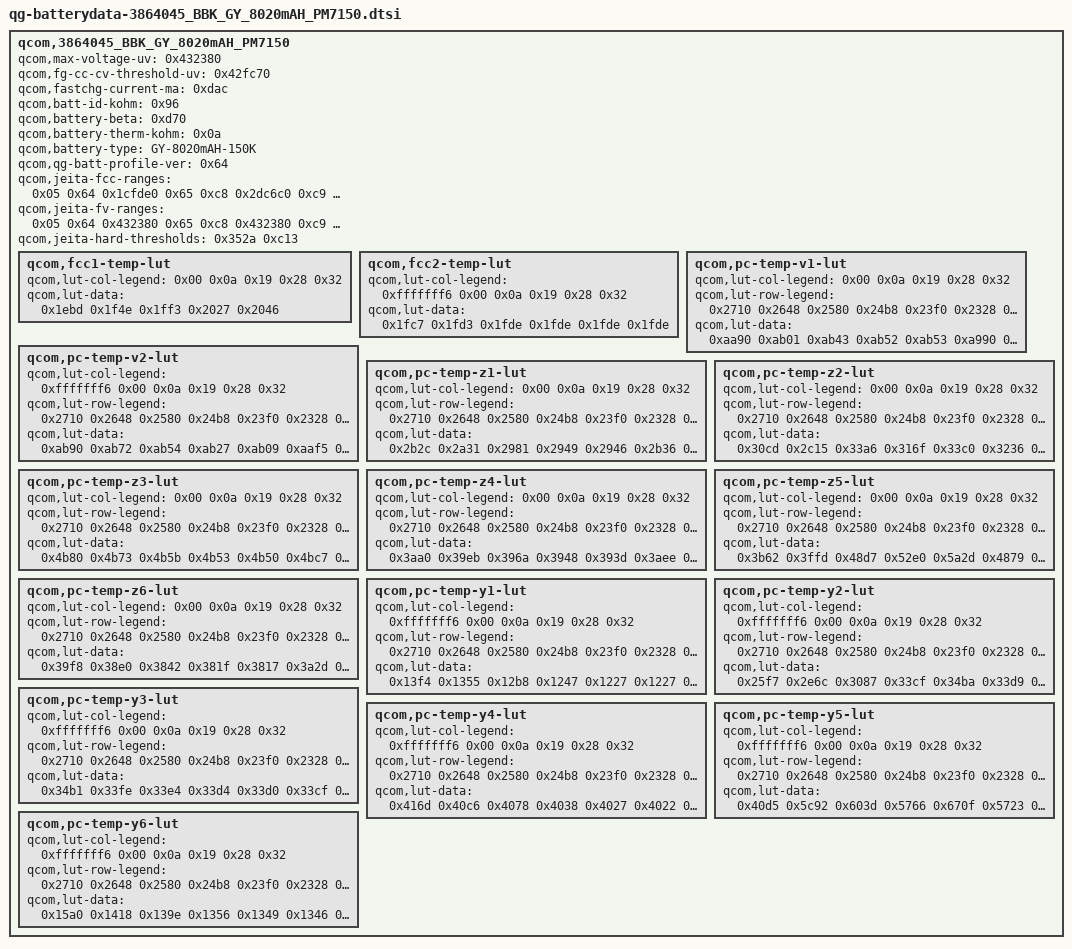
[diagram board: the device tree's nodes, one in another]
 /*
 * Copyright (c) 2026 XiKoTaSu <3329989998@qq.com>
 */

			qcom,3864045_BBK_GY_8020mAH_PM7150 {
				qcom,max-voltage-uv = <0x432380>;
				qcom,fg-cc-cv-threshold-uv = <0x42fc70>;
				qcom,fastchg-current-ma = <0xdac>;
				qcom,batt-id-kohm = <0x96>;
				qcom,battery-beta = <0xd70>;
				qcom,battery-therm-kohm = <0x0a>;
				qcom,battery-type = "GY-8020mAH-150K";
				qcom,qg-batt-profile-ver = <0x64>;
				qcom,jeita-fcc-ranges = <0x05 0x64 0x1cfde0 0x65 0xc8 0x2dc6c0 0xc9 0x1c2 0x3567e0 0x1c3 0x221 0x2625a0>;
				qcom,jeita-fv-ranges = <0x05 0x64 0x432380 0x65 0xc8 0x432380 0xc9 0x1c2 0x432380 0x1c3 0x221 0x3e8fa0>;
				qcom,jeita-hard-thresholds = <0x352a 0xc13>;

				qcom,fcc1-temp-lut {
					qcom,lut-col-legend = <0x00 0x0a 0x19 0x28 0x32>;
					qcom,lut-data = <0x1ebd 0x1f4e 0x1ff3 0x2027 0x2046>;
				};

				qcom,fcc2-temp-lut {
					qcom,lut-col-legend = <0xfffffff6 0x00 0x0a 0x19 0x28 0x32>;
					qcom,lut-data = <0x1fc7 0x1fd3 0x1fde 0x1fde 0x1fde 0x1fde>;
				};

				qcom,pc-temp-v1-lut {
					qcom,lut-col-legend = <0x00 0x0a 0x19 0x28 0x32>;
					qcom,lut-row-legend = <0x2710 0x2648 0x2580 0x24b8 0x23f0 0x2328 0x2260 0x2198 0x20d0 0x2008 0x1f40 0x1e78 0x1db0 0x1ce8 0x1c20 0x1b58 0x1a90 0x19c8 0x1900 0x1838 0x1770 0x16a8 0x15e0 0x1518 0x1450 0x1388 0x12c0 0x11f8 0x1130 0x1068 0xfa0 0xed8 0xe10 0xd48 0xc80 0xbb8 0xaf0 0xa28 0x960 0x898 0x7d0 0x708 0x640 0x578 0x4b0 0x3e8 0x384 0x320 0x2bc 0x258 0x1f4 0x190 0x12c 0xc8 0x64 0x00>;
					qcom,lut-data = <0xaa90 0xab01 0xab43 0xab52 0xab53 0xa990 0xaa10 0xaa6d 0xaa7b 0xaa7d 0xa895 0xa921 0xa98e 0xa9a4 0xa9ab 0xa7a1 0xa834 0xa8aa 0xa8c8 0xa8d4 0xa6b7 0xa749 0xa7bd 0xa7e4 0xa7f3 0xa5d5 0xa65f 0xa6cf 0xa6fb 0xa70b 0xa4fa 0xa579 0xa5e4 0xa613 0xa623 0xa427 0xa499 0xa4fb 0xa529 0xa53a 0xa35b 0xa3c0 0xa416 0xa442 0xa454 0xa290 0xa2eb 0xa334 0xa35d 0xa36e 0xa1c6 0xa21a 0xa256 0xa279 0xa28a 0xa105 0xa14b 0xa17f 0xa19d 0xa1ad 0xa059 0xa08b 0xa0ae 0xa0c3 0xa0d3 0x9fb5 0x9fe9 0x9fea 0x9ff3 0xa000 0x9ee5 0x9f42 0x9f38 0x9f2b 0x9f31 0x9daa 0x9e54 0x9e7e 0x9e69 0x9e67 0x9c7f 0x9d15 0x9d93 0x9da6 0x9da6 0x9bdb 0x9c25 0x9c99 0x9ce4 0x9ced 0x9b6e 0x9bb3 0x9be4 0x9c30 0x9c3b 0x9aff 0x9b54 0x9b6b 0x9b95 0x9b9b 0x9a87 0x9aa9 0x9ae6 0x9af6 0x9af8 0x9a04 0x9985 0x9a08 0x9a21 0x9a2b 0x9951 0x9892 0x98fc 0x9920 0x992f 0x984b 0x9813 0x983b 0x9854 0x985d 0x977c 0x97b2 0x97ae 0x97be 0x97c3 0x9722 0x9751 0x9737 0x973f 0x9741 0x96e5 0x96f2 0x96cc 0x96cc 0x96cc 0x96ac 0x969a 0x966c 0x9664 0x9663 0x9676 0x964a 0x9614 0x9606 0x9604 0x9644 0x9601 0x95c2 0x95af 0x95aa 0x9613 0x95c1 0x9579 0x9560 0x9558 0x95e3 0x9587 0x9537 0x9519 0x950e 0x95b9 0x9554 0x94fd 0x94d8 0x94ca 0x9595 0x952d 0x94cc 0x949f 0x948b 0x9574 0x950e 0x94a4 0x946e 0x9455 0x9555 0x94ed 0x947d 0x943f 0x941e 0x9539 0x94cf 0x9457 0x940a 0x93dd 0x9514 0x94aa 0x942f 0x93d2 0x9393 0x94cc 0x946d 0x93f5 0x938c 0x9342 0x9462 0x940b 0x939b 0x9332 0x92e8 0x93ef 0x939c 0x9330 0x92c9 0x9280 0x9369 0x931e 0x92b6 0x924e 0x9203 0x92d4 0x928f 0x922a 0x91c2 0x9173 0x9226 0x91e3 0x9188 0x9123 0x90d6 0x91c7 0x9160 0x9104 0x90a8 0x9064 0x9178 0x9118 0x90bf 0x9066 0x902a 0x915c 0x9103 0x90ac 0x9054 0x901c 0x9142 0x90fa 0x909d 0x904a 0x900f 0x9120 0x90e0 0x908c 0x9032 0x8ff0 0x90a6 0x9075 0x900c 0x8f98 0x8f2b 0x8f30 0x8f0b 0x8ea3 0x8e2e 0x8db4 0x8d42 0x8d28 0x8cc5 0x8c4f 0x8bcd 0x8aca 0x8abe 0x8a5d 0x89e8 0x8958 0x8765 0x876e 0x8711 0x869f 0x85f9 0x81f9 0x8236 0x81e4 0x8181 0x80a7 0x7530 0x7530 0x7530 0x7530 0x7530>;
				};

				qcom,pc-temp-v2-lut {
					qcom,lut-col-legend = <0xfffffff6 0x00 0x0a 0x19 0x28 0x32>;
					qcom,lut-row-legend = <0x2710 0x2648 0x2580 0x24b8 0x23f0 0x2328 0x2260 0x2198 0x20d0 0x2008 0x1f40 0x1e78 0x1db0 0x1ce8 0x1c20 0x1b58 0x1a90 0x19c8 0x1900 0x1838 0x1770 0x16a8 0x15e0 0x1518 0x1450 0x1388 0x12c0 0x11f8 0x1130 0x1068 0xfa0 0xed8 0xe10 0xd48 0xc80 0xbb8 0xaf0 0xa28 0x960 0x898 0x7d0 0x708 0x640 0x578 0x4b0 0x3e8 0x384 0x320 0x2bc 0x258 0x1f4 0x190 0x12c 0xc8 0x64 0x00>;
					qcom,lut-data = <0xab90 0xab72 0xab54 0xab27 0xab09 0xaaf5 0xa9f3 0xaa3a 0xaa49 0xaa27 0xaa14 0xaa02 0xa87e 0xa913 0xa945 0xa92c 0xa922 0xa913 0xa735 0xa800 0xa84a 0xa837 0xa833 0xa826 0xa60e 0xa700 0xa755 0xa749 0xa748 0xa73d 0xa50a 0xa609 0xa665 0xa65d 0xa65e 0xa654 0xa431 0xa515 0xa579 0xa572 0xa574 0xa56b 0xa36c 0xa428 0xa490 0xa489 0xa48b 0xa481 0xa28c 0xa344 0xa3ae 0xa3a5 0xa3a6 0xa39c 0xa183 0xa265 0xa2d3 0xa2c4 0xa2c2 0xa2b9 0xa0bf 0xa193 0xa1fb 0xa1e6 0xa1e2 0xa1d9 0xa06e 0xa0dc 0xa121 0xa10a 0xa106 0xa0fd 0xa030 0xa02b 0xa04b 0xa032 0xa02e 0xa024 0x9f6b 0x9f5c 0x9f89 0x9f6e 0x9f60 0x9f54 0x9d0b 0x9e6c 0x9edd 0x9ebe 0x9e99 0x9e88 0x9b08 0x9d6c 0x9e1c 0x9e02 0x9dd8 0x9dc4 0x9a55 0x9c51 0x9d11 0x9d12 0x9d15 0x9d07 0x99d9 0x9b33 0x9bee 0x9c19 0x9c57 0x9c51 0x9937 0x9a55 0x9b13 0x9b66 0x9ba6 0x9ba2 0x986b 0x99ab 0x9a6d 0x9ae6 0x9b06 0x9aff 0x979f 0x9904 0x99c4 0x9a54 0x9a56 0x9a4c 0x96d7 0x9849 0x98f5 0x9968 0x9966 0x995d 0x961e 0x9790 0x9824 0x985e 0x9866 0x9860 0x95a5 0x96f4 0x977d 0x97a0 0x97ac 0x97a8 0x9553 0x966f 0x96f4 0x9712 0x971e 0x971c 0x9513 0x95f5 0x967a 0x9697 0x96a4 0x96a2 0x94e1 0x957e 0x960b 0x9629 0x9635 0x9632 0x94b6 0x9511 0x95a7 0x95c6 0x95d1 0x95cd 0x948d 0x94bb 0x954a 0x956b 0x9575 0x956f 0x9465 0x9474 0x94f4 0x9516 0x951f 0x9518 0x943e 0x943b 0x94a5 0x94ca 0x94d1 0x94c9 0x9416 0x9413 0x945c 0x9485 0x948b 0x9483 0x93ed 0x93f1 0x9419 0x9446 0x9449 0x9440 0x93c0 0x93ce 0x93e3 0x9406 0x9405 0x93f8 0x9390 0x93aa 0x93b7 0x93c7 0x93c1 0x93ab 0x935a 0x9383 0x938c 0x9387 0x9376 0x9355 0x931e 0x9358 0x935f 0x9345 0x931a 0x92ec 0x92da 0x9327 0x932f 0x9302 0x92b6 0x927a 0x928d 0x92e4 0x92f2 0x92bb 0x925d 0x921b 0x9230 0x9284 0x92a4 0x9271 0x9210 0x91ca 0x91d1 0x9216 0x9248 0x921c 0x91bb 0x9172 0x9176 0x9196 0x91d9 0x91af 0x9150 0x9101 0x911f 0x9117 0x915b 0x9131 0x90d4 0x9084 0x90ca 0x90b9 0x90ca 0x908e 0x9034 0x8fe9 0x9073 0x9072 0x9072 0x903c 0x8fee 0x8fae 0x9009 0x9027 0x9045 0x901d 0x8fd7 0x8f9b 0x8fb4 0x8ff4 0x902c 0x900d 0x8fc9 0x8f8b 0x8f4b 0x8f93 0x900a 0x8ff9 0x8fb2 0x8f6f 0x8ec2 0x8f05 0x8fc6 0x8fd1 0x8f83 0x8f32 0x8e22 0x8e1e 0x8f22 0x8f48 0x8ecd 0x8e20 0x8d2a 0x8ccb 0x8dde 0x8dd1 0x8d3a 0x8c6c 0x8bae 0x8b1f 0x8bf1 0x8bcf 0x8b2b 0x8a3b 0x8966 0x88d0 0x8956 0x892e 0x887c 0x875b 0x85ec 0x8576 0x85af 0x8594 0x84b8 0x8332 0x7fb3 0x7fb4 0x7fa3 0x7fc5 0x7eb8 0x7c9d 0x6b66 0x6a63 0x7045 0x7061 0x7126 0x6dff>;
				};

				qcom,pc-temp-z1-lut {
					qcom,lut-col-legend = <0x00 0x0a 0x19 0x28 0x32>;
					qcom,lut-row-legend = <0x2710 0x2648 0x2580 0x24b8 0x23f0 0x2328 0x2260 0x2198 0x20d0 0x2008 0x1f40 0x1e78 0x1db0 0x1ce8 0x1c20 0x1b58 0x1a90 0x19c8 0x1900 0x1838 0x1770 0x16a8 0x15e0 0x1518 0x1450 0x1388 0x12c0 0x11f8 0x1130 0x1068 0xfa0 0xed8 0xe10 0xd48 0xc80 0xbb8 0xaf0 0xa28 0x960 0x898 0x7d0 0x708 0x640 0x578 0x4b0 0x3e8 0x384 0x320 0x2bc 0x258 0x1f4 0x190 0x12c 0xc8 0x64 0x00>;
					qcom,lut-data = <0x2b2c 0x2a31 0x2981 0x2949 0x2946 0x2b36 0x2a41 0x2999 0x295d 0x295f 0x2b39 0x2a48 0x29a0 0x2964 0x2965 0x2b3a 0x2a4a 0x29a1 0x2967 0x2968 0x2b3c 0x2a4b 0x29a0 0x2969 0x296a 0x2b3d 0x2a4b 0x29a0 0x296a 0x296c 0x2b3d 0x2a49 0x29a1 0x296c 0x296e 0x2b3b 0x2a48 0x29a2 0x296d 0x2971 0x2b39 0x2a48 0x29a2 0x296d 0x2972 0x2b38 0x2a48 0x29a2 0x296d 0x2972 0x2b36 0x2a48 0x29a1 0x296c 0x2972 0x2b35 0x2a4a 0x29a1 0x296c 0x2972 0x2b35 0x2a4a 0x29a1 0x296c 0x2972 0x2b37 0x2a44 0x29a0 0x296c 0x2972 0x2b36 0x2a3b 0x299e 0x296c 0x2972 0x2b2e 0x2a39 0x299c 0x296c 0x2972 0x2b26 0x2a3a 0x299c 0x296c 0x2972 0x2b25 0x2a3a 0x299b 0x296c 0x2973 0x2b27 0x2a3b 0x299c 0x296c 0x2973 0x2b29 0x2a3b 0x299e 0x296d 0x2973 0x2b2b 0x2a3c 0x29a0 0x296e 0x2974 0x2b2e 0x2a3c 0x29a1 0x296f 0x2974 0x2b32 0x2a3d 0x29a3 0x2970 0x2976 0x2b3a 0x2a3e 0x29a4 0x2971 0x2977 0x2b41 0x2a3e 0x29a6 0x2971 0x2977 0x2b40 0x2a40 0x29a8 0x2972 0x2978 0x2b3e 0x2a44 0x29a8 0x2972 0x2979 0x2b3f 0x2a49 0x29a9 0x2973 0x297a 0x2b44 0x2a4a 0x29ab 0x2974 0x297a 0x2b48 0x2a4a 0x29ae 0x2975 0x297c 0x2b48 0x2a4b 0x29b1 0x2977 0x297d 0x2b48 0x2a4a 0x29b2 0x2978 0x297d 0x2b48 0x2a4a 0x29b2 0x2979 0x297e 0x2b4a 0x2a4b 0x29b2 0x297a 0x297f 0x2b4b 0x2a4b 0x29b3 0x297b 0x297f 0x2b4c 0x2a4d 0x29b4 0x297c 0x2980 0x2b4d 0x2a50 0x29b6 0x297d 0x2981 0x2b4f 0x2a53 0x29b8 0x297e 0x2982 0x2b55 0x2a53 0x29ba 0x297f 0x2983 0x2b5d 0x2a53 0x29bc 0x2980 0x2983 0x2b60 0x2a53 0x29bd 0x2981 0x2984 0x2b5f 0x2a59 0x29be 0x2982 0x2985 0x2b5c 0x2a5e 0x29be 0x2983 0x2986 0x2b4a 0x2a5f 0x29bf 0x2985 0x2986 0x2b4d 0x2a61 0x29c1 0x2985 0x2987 0x2b56 0x2a59 0x29c2 0x2985 0x2987 0x2b57 0x2a5c 0x29c4 0x2986 0x2988 0x2b50 0x2a5e 0x29c4 0x2986 0x2987 0x2b62 0x2a5a 0x29c2 0x2986 0x2987 0x2b60 0x2a60 0x29c6 0x2988 0x2989 0x2b56 0x2a63 0x29c9 0x298a 0x298b 0x2b5b 0x2a64 0x29ce 0x298d 0x298e 0x2b69 0x2a6a 0x29d1 0x2991 0x2991 0x2b7e 0x2a79 0x29d6 0x2996 0x2995 0x2b7e 0x2a79 0x29d6 0x2996 0x2995 0x2b7e 0x2a79 0x29d6 0x2996 0x2995>;
				};

				qcom,pc-temp-z2-lut {
					qcom,lut-col-legend = <0x00 0x0a 0x19 0x28 0x32>;
					qcom,lut-row-legend = <0x2710 0x2648 0x2580 0x24b8 0x23f0 0x2328 0x2260 0x2198 0x20d0 0x2008 0x1f40 0x1e78 0x1db0 0x1ce8 0x1c20 0x1b58 0x1a90 0x19c8 0x1900 0x1838 0x1770 0x16a8 0x15e0 0x1518 0x1450 0x1388 0x12c0 0x11f8 0x1130 0x1068 0xfa0 0xed8 0xe10 0xd48 0xc80 0xbb8 0xaf0 0xa28 0x960 0x898 0x7d0 0x708 0x640 0x578 0x4b0 0x3e8 0x384 0x320 0x2bc 0x258 0x1f4 0x190 0x12c 0xc8 0x64 0x00>;
					qcom,lut-data = <0x30cd 0x2c15 0x33a6 0x316f 0x33c0 0x3236 0x2e8c 0x30f5 0x3098 0x31bb 0x3033 0x2f43 0x30df 0x30bf 0x3165 0x2e33 0x2f3c 0x30e4 0x30e3 0x312f 0x2dea 0x2f30 0x30f5 0x30ab 0x30d9 0x2dc2 0x2f11 0x30fd 0x305e 0x3076 0x2d99 0x2ede 0x30e4 0x304f 0x3058 0x2d6d 0x2ec8 0x30c3 0x3045 0x3070 0x2d45 0x2ec9 0x30b8 0x304e 0x3086 0x2d2f 0x2ecb 0x30c5 0x307f 0x3097 0x2d21 0x2ecf 0x30cd 0x30b3 0x30b8 0x2d1a 0x2edd 0x30aa 0x30b8 0x30cb 0x2d8d 0x2eeb 0x306c 0x30a2 0x30d8 0x2e69 0x2f09 0x3052 0x3098 0x30e6 0x2ea0 0x2f25 0x304a 0x30a9 0x30f7 0x2e06 0x2f0e 0x303f 0x30bd 0x3108 0x2d68 0x2ea9 0x2ffc 0x30bd 0x3118 0x2d46 0x2e72 0x2f91 0x30b6 0x3129 0x2d2f 0x2ea3 0x2f7f 0x30b7 0x3139 0x2d28 0x2eea 0x2fcd 0x30f1 0x3175 0x2d50 0x2eff 0x3042 0x3147 0x31b9 0x2d87 0x2f03 0x3101 0x319a 0x31ae 0x2d88 0x2f06 0x31e0 0x31fb 0x3153 0x2d57 0x2f11 0x31f8 0x320a 0x30da 0x2d33 0x2f1f 0x312c 0x30c6 0x2ff7 0x2d52 0x2f21 0x306d 0x2f7d 0x2f2c 0x2d91 0x2f13 0x3023 0x2f61 0x2f20 0x2da5 0x2f00 0x2ff2 0x2f61 0x2f37 0x2da2 0x2ee5 0x2fed 0x2f6d 0x2f58 0x2d9f 0x2ec5 0x300e 0x2f8d 0x2f93 0x2da2 0x2ebf 0x302e 0x2fb5 0x2fde 0x2dad 0x2edb 0x3046 0x2ff4 0x301f 0x2db6 0x2f00 0x306d 0x3065 0x3060 0x2dc2 0x2f1b 0x30a8 0x30ce 0x30b4 0x2dcd 0x2f36 0x3119 0x3138 0x3138 0x2dd1 0x2f4f 0x317a 0x319e 0x31bf 0x2dd9 0x2f68 0x31a8 0x3202 0x322e 0x2de3 0x2f83 0x31cb 0x3262 0x3292 0x2df1 0x2fa9 0x31f6 0x3292 0x32b1 0x2e00 0x2fd9 0x3231 0x32ac 0x329e 0x2e03 0x2feb 0x3250 0x32b2 0x3287 0x2df5 0x2fd3 0x323c 0x3299 0x327c 0x2de3 0x2fbc 0x320a 0x326f 0x3269 0x2dca 0x2fa0 0x318e 0x323a 0x3223 0x2f8a 0x2fa0 0x317e 0x323c 0x31ea 0x33ba 0x2f95 0x319b 0x3246 0x321d 0x348d 0x2f6a 0x3154 0x3244 0x3237 0x39eb 0x2f3c 0x3155 0x32bb 0x3276 0x3d3e 0x2f3f 0x31e7 0x33a8 0x33d3 0x3928 0x2fe2 0x327f 0x328e 0x314c 0x40f9 0x3015 0x319c 0x3107 0x303a 0x3197 0x2fe8 0x3132 0x3076 0x2fe0 0x2cdb 0x2f18 0x311d 0x3026 0x2f61 0x29ec 0x2e1f 0x303c 0x2f76 0x2eac 0x29ec 0x2e1f 0x303c 0x2f76 0x2eac 0x29ec 0x2e1f 0x303c 0x2f76 0x2eac>;
				};

				qcom,pc-temp-z3-lut {
					qcom,lut-col-legend = <0x00 0x0a 0x19 0x28 0x32>;
					qcom,lut-row-legend = <0x2710 0x2648 0x2580 0x24b8 0x23f0 0x2328 0x2260 0x2198 0x20d0 0x2008 0x1f40 0x1e78 0x1db0 0x1ce8 0x1c20 0x1b58 0x1a90 0x19c8 0x1900 0x1838 0x1770 0x16a8 0x15e0 0x1518 0x1450 0x1388 0x12c0 0x11f8 0x1130 0x1068 0xfa0 0xed8 0xe10 0xd48 0xc80 0xbb8 0xaf0 0xa28 0x960 0x898 0x7d0 0x708 0x640 0x578 0x4b0 0x3e8 0x384 0x320 0x2bc 0x258 0x1f4 0x190 0x12c 0xc8 0x64 0x00>;
					qcom,lut-data = <0x4b80 0x4b73 0x4b5b 0x4b53 0x4b50 0x4bc7 0x4b8f 0x4b67 0x4b59 0x4b55 0x4bd1 0x4b9c 0x4b6f 0x4b5e 0x4b57 0x4bdd 0x4ba3 0x4b73 0x4b60 0x4b58 0x4be1 0x4ba6 0x4b76 0x4b61 0x4b5a 0x4be3 0x4ba7 0x4b77 0x4b61 0x4b5c 0x4be4 0x4ba7 0x4b77 0x4b61 0x4b5c 0x4be4 0x4ba7 0x4b76 0x4b61 0x4b5c 0x4be3 0x4ba5 0x4b75 0x4b60 0x4b5c 0x4be3 0x4ba3 0x4b74 0x4b60 0x4b5b 0x4be2 0x4ba1 0x4b73 0x4b60 0x4b5b 0x4be1 0x4b9f 0x4b71 0x4b5e 0x4b5a 0x4bdc 0x4b9d 0x4b6f 0x4b5b 0x4b58 0x4bd3 0x4b98 0x4b6d 0x4b5a 0x4b57 0x4bd0 0x4b93 0x4b6c 0x4b5a 0x4b56 0x4bd6 0x4b95 0x4b6c 0x4b5a 0x4b56 0x4bdc 0x4b9d 0x4b6c 0x4b5a 0x4b56 0x4bda 0x4ba2 0x4b6d 0x4b59 0x4b55 0x4bd2 0x4b9c 0x4b6d 0x4b59 0x4b54 0x4bcc 0x4b93 0x4b69 0x4b58 0x4b53 0x4bcb 0x4b93 0x4b67 0x4b57 0x4b52 0x4bca 0x4b98 0x4b69 0x4b5a 0x4b55 0x4bca 0x4b9b 0x4b6f 0x4b64 0x4b5f 0x4bcc 0x4b98 0x4b75 0x4b68 0x4b63 0x4bce 0x4b94 0x4b7d 0x4b68 0x4b63 0x4bcf 0x4b95 0x4b81 0x4b67 0x4b63 0x4bd0 0x4b9e 0x4b80 0x4b67 0x4b62 0x4bd0 0x4ba5 0x4b7c 0x4b66 0x4b5f 0x4bd0 0x4ba5 0x4b7a 0x4b65 0x4b5d 0x4bd0 0x4ba3 0x4b78 0x4b63 0x4b5b 0x4bd1 0x4ba2 0x4b77 0x4b61 0x4b5a 0x4bd1 0x4ba0 0x4b75 0x4b60 0x4b58 0x4bd0 0x4b9e 0x4b73 0x4b5e 0x4b57 0x4bcf 0x4b9c 0x4b71 0x4b5d 0x4b56 0x4bcd 0x4b99 0x4b6f 0x4b5b 0x4b54 0x4bcb 0x4b97 0x4b6d 0x4b5a 0x4b53 0x4bc9 0x4b96 0x4b6d 0x4b59 0x4b53 0x4bc7 0x4b95 0x4b6c 0x4b59 0x4b54 0x4bc4 0x4b93 0x4b6b 0x4b59 0x4b55 0x4bc1 0x4b91 0x4b69 0x4b59 0x4b56 0x4bc0 0x4b8e 0x4b68 0x4b59 0x4b57 0x4bbf 0x4b8d 0x4b67 0x4b5a 0x4b57 0x4bbe 0x4b8c 0x4b67 0x4b5a 0x4b58 0x4bba 0x4b8c 0x4b66 0x4b5b 0x4b59 0x4b54 0x4b87 0x4b65 0x4b5a 0x4b58 0x4b39 0x4b82 0x4b61 0x4b57 0x4b55 0x4b39 0x4b81 0x4b5f 0x4b56 0x4b50 0x4b39 0x4b72 0x4b60 0x4b51 0x4b4e 0x4b39 0x4b6c 0x4b5a 0x4b4f 0x4b4c 0x4b39 0x4b69 0x4b5b 0x4b54 0x4b53 0x4b39 0x4b66 0x4b60 0x4b57 0x4b55 0x4b3a 0x4b64 0x4b5f 0x4b59 0x4b55 0x4b3b 0x4b62 0x4b5c 0x4b58 0x4b56 0x4b3c 0x4b62 0x4b5d 0x4b5a 0x4b57 0x4b3c 0x4b62 0x4b5d 0x4b5a 0x4b57 0x4b3c 0x4b62 0x4b5d 0x4b5a 0x4b57>;
				};

				qcom,pc-temp-z4-lut {
					qcom,lut-col-legend = <0x00 0x0a 0x19 0x28 0x32>;
					qcom,lut-row-legend = <0x2710 0x2648 0x2580 0x24b8 0x23f0 0x2328 0x2260 0x2198 0x20d0 0x2008 0x1f40 0x1e78 0x1db0 0x1ce8 0x1c20 0x1b58 0x1a90 0x19c8 0x1900 0x1838 0x1770 0x16a8 0x15e0 0x1518 0x1450 0x1388 0x12c0 0x11f8 0x1130 0x1068 0xfa0 0xed8 0xe10 0xd48 0xc80 0xbb8 0xaf0 0xa28 0x960 0x898 0x7d0 0x708 0x640 0x578 0x4b0 0x3e8 0x384 0x320 0x2bc 0x258 0x1f4 0x190 0x12c 0xc8 0x64 0x00>;
					qcom,lut-data = <0x3aa0 0x39eb 0x396a 0x3948 0x393d 0x3aee 0x3a20 0x3999 0x395c 0x394a 0x3ac2 0x3a28 0x398d 0x3958 0x3948 0x3a83 0x39f8 0x3980 0x3953 0x3944 0x3a4c 0x39c0 0x396f 0x394b 0x393f 0x3a15 0x39a0 0x395e 0x3942 0x3938 0x39e6 0x3988 0x3950 0x393a 0x3932 0x39c1 0x3973 0x3944 0x3933 0x392d 0x39a3 0x3960 0x393d 0x392e 0x3928 0x398f 0x3952 0x3938 0x392b 0x3926 0x3982 0x3950 0x3936 0x3928 0x3924 0x3975 0x3950 0x3935 0x3927 0x3922 0x3962 0x394f 0x3935 0x3925 0x3920 0x394d 0x3946 0x3934 0x3923 0x391e 0x3949 0x393c 0x392d 0x3920 0x391c 0x3963 0x393d 0x3928 0x391c 0x3919 0x397f 0x3948 0x3928 0x3919 0x3917 0x397a 0x394e 0x3928 0x3917 0x3915 0x3962 0x3942 0x3928 0x3916 0x3913 0x3952 0x3931 0x3925 0x3916 0x3912 0x394d 0x393c 0x3923 0x3916 0x3912 0x394a 0x3980 0x393a 0x391f 0x3917 0x3956 0x39ad 0x3964 0x3939 0x392c 0x3997 0x39a7 0x396c 0x3943 0x3937 0x39c7 0x399a 0x395a 0x393d 0x3932 0x39bf 0x398a 0x3949 0x3934 0x392b 0x39ac 0x3973 0x3942 0x392f 0x3927 0x399c 0x3962 0x393e 0x392c 0x3925 0x398d 0x395a 0x393a 0x3928 0x3922 0x3980 0x3955 0x3937 0x3926 0x3920 0x3978 0x3954 0x3936 0x3924 0x391f 0x3971 0x3955 0x3936 0x3922 0x391d 0x396b 0x3956 0x3936 0x3921 0x391b 0x3968 0x3955 0x3936 0x3921 0x391b 0x3964 0x3954 0x3937 0x3921 0x391b 0x3960 0x3952 0x3937 0x3922 0x391b 0x395a 0x394f 0x3938 0x3924 0x391d 0x3956 0x394d 0x3938 0x3927 0x3922 0x3956 0x394c 0x3938 0x3928 0x3923 0x3956 0x394c 0x3938 0x3928 0x3922 0x3956 0x394b 0x3937 0x3927 0x3920 0x3951 0x3945 0x3933 0x3924 0x391f 0x394c 0x393e 0x392f 0x3922 0x391e 0x3947 0x393b 0x392e 0x3922 0x391f 0x398f 0x392f 0x3928 0x3920 0x391c 0x399e 0x3922 0x391d 0x3916 0x3912 0x3999 0x391d 0x3917 0x3912 0x3910 0x3996 0x3924 0x3910 0x390d 0x390a 0x3990 0x3927 0x3910 0x390a 0x3907 0x398d 0x392a 0x3915 0x390d 0x390d 0x3996 0x3934 0x3914 0x390d 0x390d 0x399a 0x3939 0x3915 0x390c 0x390d 0x399e 0x393e 0x3918 0x390d 0x390c 0x39a8 0x3942 0x3919 0x390c 0x390c 0x39a8 0x3942 0x3919 0x390c 0x390c 0x39a8 0x3942 0x3919 0x390c 0x390c>;
				};

				qcom,pc-temp-z5-lut {
					qcom,lut-col-legend = <0x00 0x0a 0x19 0x28 0x32>;
					qcom,lut-row-legend = <0x2710 0x2648 0x2580 0x24b8 0x23f0 0x2328 0x2260 0x2198 0x20d0 0x2008 0x1f40 0x1e78 0x1db0 0x1ce8 0x1c20 0x1b58 0x1a90 0x19c8 0x1900 0x1838 0x1770 0x16a8 0x15e0 0x1518 0x1450 0x1388 0x12c0 0x11f8 0x1130 0x1068 0xfa0 0xed8 0xe10 0xd48 0xc80 0xbb8 0xaf0 0xa28 0x960 0x898 0x7d0 0x708 0x640 0x578 0x4b0 0x3e8 0x384 0x320 0x2bc 0x258 0x1f4 0x190 0x12c 0xc8 0x64 0x00>;
					qcom,lut-data = <0x3b62 0x3ffd 0x48d7 0x52e0 0x5a2d 0x4879 0x4f03 0x588e 0x62c5 0x6b03 0x4f72 0x5963 0x601d 0x6e6c 0x6e66 0x5650 0x603b 0x6611 0x7458 0x7232 0x5c33 0x664f 0x6b3d 0x74e8 0x7792 0x6112 0x6ced 0x7037 0x7540 0x7e09 0x66a1 0x739f 0x7631 0x76eb 0x8358 0x6e29 0x7bb9 0x7c57 0x7bd0 0x8819 0x771c 0x8826 0x80a0 0x80ba 0x8c11 0x8111 0x9310 0x8498 0x857f 0x909c 0x8df6 0x966e 0x86d1 0x8919 0x9522 0x95c2 0x96b5 0x83a3 0x8772 0x94da 0x9547 0x963c 0x7d53 0x8044 0x8e92 0x93fd 0x938e 0x7c33 0x7ce9 0x8a86 0x938e 0x9110 0x815c 0x8102 0x8f7c 0x9405 0x9352 0x87b7 0x884b 0x98f7 0x94c8 0x99ae 0x8c69 0x9135 0xa0df 0x95a9 0xa0b6 0x9143 0x9ce0 0xa8bf 0x978d 0xa6b2 0x979f 0xa1f0 0xad1e 0x9b13 0xadd2 0xa19e 0xa1fd 0xaeb8 0xb2e1 0xbc62 0xa7d0 0xa0d3 0xafa4 0xd4d8 0xdae1 0x9af0 0x9bcf 0xac2a 0xe3e1 0xecce 0x82f4 0x9008 0x9e44 0xec8c 0xc626 0x7d62 0x865d 0x9278 0xee7f 0x8662 0x8114 0x7d15 0x8ad7 0xde79 0x799a 0x862a 0x76c3 0x855d 0xc3bc 0x8a34 0x8b46 0x79dd 0x849c 0xb9a4 0x9ef3 0x916f 0x840c 0x87ce 0xb862 0xb0bc 0x99b7 0x8cf3 0x8970 0xb8d9 0xc2d3 0xa89a 0x93a3 0x8af0 0xbfbf 0xd205 0xb654 0x9adf 0x8e1e 0xd1e5 0xe08f 0xc15b 0xa578 0x9450 0xdfec 0xe9d5 0xccc5 0xb21d 0x9e2f 0xe938 0xebb0 0xd360 0xba1c 0xa4f5 0xf02d 0xec99 0xd7ef 0xbfb6 0xa9e4 0xf19f 0xed24 0xd9fd 0xc2a5 0xacca 0xf187 0xef9a 0xd75f 0xbaf8 0xac5b 0xf19e 0xf1fd 0xd0d3 0xaaf4 0xab1b 0xf3d9 0xedba 0xc78c 0xa62c 0xab72 0xf721 0xdf8a 0xb6b5 0xa5eb 0xb39c 0xf6e7 0xd4cf 0xab42 0xa5e5 0xbd48 0xec43 0xcd36 0xa9a5 0xaa49 0xc3d1 0xe0b5 0xc7b9 0xa825 0xafef 0xc7e9 0xd6d4 0xc520 0x98ff 0xabaf 0xc486 0x540e 0xc32d 0x9bb5 0x9c27 0xb444 0x333e 0xb948 0x9532 0x9510 0xa2ce 0x328f 0xbf66 0x9ba3 0xa099 0x87a0 0x3248 0x6e55 0xb53d 0x96f5 0x9f2b 0x3249 0x621d 0x8d04 0x9fcc 0xaf5c 0x32eb 0x5e74 0x82a6 0x9ed5 0xb2e9 0x32f4 0x52da 0x8a4b 0x9c98 0xad17 0x3278 0x4d0c 0x7cfc 0xa5d7 0xa613 0x3202 0x47c6 0x68b8 0x9787 0xa969 0x3126 0x44bb 0x6522 0x9b4f 0xa49f 0x3126 0x44bb 0x6522 0x9b4f 0xa49f 0x3126 0x44bb 0x6522 0x9b4f 0xa49f>;
				};

				qcom,pc-temp-z6-lut {
					qcom,lut-col-legend = <0x00 0x0a 0x19 0x28 0x32>;
					qcom,lut-row-legend = <0x2710 0x2648 0x2580 0x24b8 0x23f0 0x2328 0x2260 0x2198 0x20d0 0x2008 0x1f40 0x1e78 0x1db0 0x1ce8 0x1c20 0x1b58 0x1a90 0x19c8 0x1900 0x1838 0x1770 0x16a8 0x15e0 0x1518 0x1450 0x1388 0x12c0 0x11f8 0x1130 0x1068 0xfa0 0xed8 0xe10 0xd48 0xc80 0xbb8 0xaf0 0xa28 0x960 0x898 0x7d0 0x708 0x640 0x578 0x4b0 0x3e8 0x384 0x320 0x2bc 0x258 0x1f4 0x190 0x12c 0xc8 0x64 0x00>;
					qcom,lut-data = <0x39f8 0x38e0 0x3842 0x381f 0x3817 0x3a2d 0x3901 0x385c 0x382d 0x3824 0x3a0f 0x3907 0x385d 0x382f 0x3826 0x39e1 0x38f1 0x385c 0x3830 0x3826 0x39bd 0x38d6 0x3855 0x382e 0x3825 0x399b 0x38c4 0x384e 0x382a 0x3824 0x397e 0x38b6 0x3848 0x3827 0x3822 0x3965 0x38aa 0x3842 0x3824 0x3820 0x3950 0x389d 0x383e 0x3822 0x381e 0x3941 0x3894 0x383b 0x3820 0x381d 0x3936 0x3891 0x3839 0x381f 0x381b 0x392b 0x3890 0x3838 0x381d 0x381a 0x391b 0x388d 0x3837 0x381b 0x3818 0x390a 0x3885 0x3835 0x3819 0x3817 0x3905 0x387c 0x3831 0x3817 0x3815 0x3912 0x387e 0x382e 0x3816 0x3814 0x391e 0x3885 0x382e 0x3815 0x3813 0x391b 0x388a 0x382f 0x3814 0x3812 0x390c 0x3882 0x382f 0x3813 0x3811 0x3904 0x3878 0x382c 0x3812 0x3810 0x3904 0x387c 0x382a 0x3812 0x380f 0x3904 0x389d 0x3836 0x3818 0x3813 0x390a 0x38b2 0x384c 0x3829 0x3822 0x3929 0x38af 0x3851 0x3830 0x3829 0x393f 0x38a8 0x384e 0x382d 0x3827 0x393d 0x38a3 0x384a 0x3829 0x3824 0x3937 0x389f 0x3847 0x3827 0x3822 0x3932 0x389b 0x3844 0x3825 0x3820 0x392c 0x3899 0x3841 0x3823 0x381e 0x3928 0x3896 0x3840 0x3821 0x381c 0x3925 0x3895 0x383e 0x381f 0x381a 0x3922 0x3895 0x383e 0x381e 0x3819 0x3920 0x3895 0x383d 0x381d 0x3818 0x391f 0x3895 0x383c 0x381c 0x3816 0x391e 0x3893 0x383c 0x381b 0x3815 0x391e 0x3893 0x383b 0x381b 0x3815 0x391d 0x3892 0x383c 0x381b 0x3816 0x391c 0x3891 0x383c 0x381d 0x3819 0x391d 0x3891 0x383c 0x381d 0x381a 0x391d 0x3891 0x383b 0x381d 0x381a 0x391e 0x3891 0x383a 0x381d 0x3819 0x3920 0x388f 0x3839 0x381c 0x3819 0x3921 0x388d 0x3838 0x381c 0x3819 0x3920 0x388e 0x3837 0x381d 0x381a 0x3914 0x3888 0x3834 0x381b 0x3819 0x390e 0x3882 0x382e 0x3816 0x3813 0x390d 0x3880 0x382b 0x3813 0x380f 0x390d 0x387c 0x3828 0x380f 0x380c 0x390d 0x387b 0x3825 0x380c 0x380a 0x390d 0x387d 0x3829 0x3811 0x3810 0x3917 0x3882 0x382c 0x3813 0x3812 0x391d 0x3885 0x382d 0x3814 0x3813 0x3926 0x3889 0x382f 0x3815 0x3814 0x3934 0x3891 0x3831 0x3817 0x3816 0x3934 0x3891 0x3831 0x3817 0x3816 0x3934 0x3891 0x3831 0x3817 0x3816>;
				};

				qcom,pc-temp-y1-lut {
					qcom,lut-col-legend = <0xfffffff6 0x00 0x0a 0x19 0x28 0x32>;
					qcom,lut-row-legend = <0x2710 0x2648 0x2580 0x24b8 0x23f0 0x2328 0x2260 0x2198 0x20d0 0x2008 0x1f40 0x1e78 0x1db0 0x1ce8 0x1c20 0x1b58 0x1a90 0x19c8 0x1900 0x1838 0x1770 0x16a8 0x15e0 0x1518 0x1450 0x1388 0x12c0 0x11f8 0x1130 0x1068 0xfa0 0xed8 0xe10 0xd48 0xc80 0xbb8 0xaf0 0xa28 0x960 0x898 0x7d0 0x708 0x640 0x578 0x4b0 0x3e8 0x384 0x320 0x2bc 0x258 0x1f4 0x190 0x12c 0xc8 0x64 0x00>;
					qcom,lut-data = <0x13f4 0x1355 0x12b8 0x1247 0x1227 0x1227 0x13ff 0x134a 0x12b6 0x124a 0x1228 0x1226 0x140a 0x1341 0x12b4 0x124c 0x1228 0x1225 0x1413 0x133b 0x12b2 0x124d 0x1228 0x1225 0x1419 0x1338 0x12b0 0x124d 0x1229 0x1224 0x141b 0x1336 0x12ae 0x124d 0x1228 0x1224 0x141a 0x1338 0x12ad 0x124b 0x1228 0x1224 0x1416 0x133b 0x12ac 0x1249 0x1227 0x1224 0x1412 0x133a 0x12ab 0x1248 0x1226 0x1224 0x140a 0x1334 0x12ab 0x1248 0x1225 0x1223 0x1405 0x1330 0x12ab 0x1248 0x1224 0x1223 0x1409 0x1330 0x12aa 0x1247 0x1224 0x1223 0x1411 0x1332 0x12a8 0x1246 0x1224 0x1223 0x1413 0x1332 0x12a8 0x1246 0x1224 0x1222 0x1414 0x1331 0x12a7 0x1245 0x1224 0x1221 0x1415 0x1330 0x12a6 0x1245 0x1223 0x1221 0x1411 0x1333 0x12a5 0x1245 0x1223 0x1221 0x140b 0x1338 0x12a5 0x1245 0x1223 0x1222 0x140a 0x133a 0x12a5 0x1245 0x1223 0x1222 0x140d 0x133b 0x12a7 0x1245 0x1223 0x1223 0x140f 0x133b 0x12a7 0x1245 0x1224 0x1223 0x1411 0x133a 0x12a7 0x1245 0x1224 0x1223 0x1414 0x1338 0x12a7 0x1245 0x1224 0x1223 0x1414 0x1338 0x12a7 0x1246 0x1224 0x1223 0x1410 0x1338 0x12a8 0x1248 0x1224 0x1224 0x140d 0x1338 0x12aa 0x1249 0x1224 0x1224 0x140b 0x1339 0x12ab 0x1249 0x1225 0x1225 0x1408 0x1339 0x12ac 0x124a 0x1226 0x1225 0x1408 0x1339 0x12ac 0x124a 0x1227 0x1226 0x140c 0x1337 0x12ac 0x124a 0x1227 0x1226 0x1410 0x1336 0x12ac 0x124b 0x1227 0x1226 0x1411 0x1336 0x12ad 0x124c 0x1228 0x1227 0x1413 0x1335 0x12ae 0x124e 0x1229 0x1227 0x1415 0x1336 0x12ae 0x124f 0x1229 0x1228 0x1416 0x1337 0x12ad 0x1251 0x1229 0x1228 0x1416 0x1339 0x12ac 0x1252 0x122a 0x1229 0x1410 0x133b 0x12ad 0x1252 0x122b 0x1229 0x1408 0x133d 0x12af 0x1252 0x122e 0x122a 0x1405 0x133d 0x12b1 0x1253 0x122f 0x122b 0x1404 0x133d 0x12b6 0x1255 0x122f 0x122c 0x1404 0x133d 0x12b9 0x1257 0x122f 0x122c 0x1405 0x1340 0x12b8 0x1258 0x122f 0x122d 0x1407 0x1343 0x12b7 0x1259 0x1230 0x122d 0x140e 0x133e 0x12b6 0x125b 0x1231 0x122d 0x1414 0x133c 0x12b8 0x125c 0x1232 0x122e 0x1417 0x1341 0x12bf 0x125c 0x1232 0x122f 0x1416 0x133d 0x12bc 0x125f 0x1235 0x122f 0x140d 0x1346 0x12be 0x125c 0x1234 0x122f 0x1417 0x1342 0x12b9 0x125e 0x1233 0x122f 0x1410 0x1340 0x12b9 0x125e 0x1234 0x122e 0x141f 0x1347 0x12bb 0x1261 0x1236 0x1230 0x1427 0x1345 0x12c2 0x1263 0x1237 0x1233 0x1432 0x134c 0x12c6 0x1266 0x1239 0x1235 0x1431 0x1355 0x12ce 0x126e 0x123c 0x1237 0x1431 0x1355 0x12ce 0x126e 0x123c 0x1237 0x1431 0x1355 0x12ce 0x126e 0x123c 0x1237>;
				};

				qcom,pc-temp-y2-lut {
					qcom,lut-col-legend = <0xfffffff6 0x00 0x0a 0x19 0x28 0x32>;
					qcom,lut-row-legend = <0x2710 0x2648 0x2580 0x24b8 0x23f0 0x2328 0x2260 0x2198 0x20d0 0x2008 0x1f40 0x1e78 0x1db0 0x1ce8 0x1c20 0x1b58 0x1a90 0x19c8 0x1900 0x1838 0x1770 0x16a8 0x15e0 0x1518 0x1450 0x1388 0x12c0 0x11f8 0x1130 0x1068 0xfa0 0xed8 0xe10 0xd48 0xc80 0xbb8 0xaf0 0xa28 0x960 0x898 0x7d0 0x708 0x640 0x578 0x4b0 0x3e8 0x384 0x320 0x2bc 0x258 0x1f4 0x190 0x12c 0xc8 0x64 0x00>;
					qcom,lut-data = <0x25f7 0x2e6c 0x3087 0x33cf 0x34ba 0x33d9 0x25e8 0x2e6b 0x308f 0x33b1 0x344b 0x33ce 0x25e0 0x2e69 0x3088 0x336c 0x33e0 0x33b5 0x25e0 0x2e66 0x3077 0x3311 0x337c 0x3392 0x25e7 0x2e63 0x3065 0x32b3 0x3321 0x3365 0x25f5 0x2e5f 0x3056 0x3263 0x32d1 0x3331 0x273d 0x2e59 0x3047 0x3201 0x3285 0x32f4 0x293a 0x2e53 0x3033 0x31a2 0x3245 0x32ae 0x294c 0x2e4f 0x301d 0x319a 0x322b 0x325e 0x2762 0x2e41 0x2ffe 0x31c5 0x3224 0x31fb 0x2614 0x2e38 0x2feb 0x31e2 0x3223 0x31c8 0x2616 0x2e4f 0x2fe8 0x31c5 0x3213 0x31e0 0x261b 0x2e86 0x2feb 0x318e 0x31f7 0x3207 0x261b 0x2ef3 0x2ffb 0x315d 0x31de 0x31fa 0x2610 0x3033 0x303d 0x311c 0x319a 0x3194 0x2608 0x30fd 0x3099 0x30fa 0x316f 0x3152 0x2606 0x309b 0x3143 0x316f 0x31d6 0x3169 0x2604 0x2ff2 0x31fb 0x325b 0x327a 0x3197 0x2600 0x2fae 0x3210 0x333a 0x32a1 0x31c1 0x25f7 0x2f8a 0x31c9 0x343d 0x328c 0x31ec 0x25ee 0x2f77 0x3182 0x34c2 0x3285 0x3220 0x25ea 0x2f71 0x314c 0x343c 0x32ec 0x3290 0x25e6 0x2f6e 0x3121 0x336d 0x3387 0x332f 0x25e3 0x2f7d 0x3122 0x334f 0x33bb 0x33d2 0x25e0 0x2fb0 0x3154 0x3388 0x33c5 0x34c3 0x25dd 0x2fd1 0x3187 0x33b9 0x33d5 0x354c 0x25d9 0x2dd5 0x31bf 0x33e5 0x3421 0x3534 0x25d6 0x2a88 0x31fa 0x3416 0x3490 0x3509 0x25d3 0x29f4 0x3207 0x342e 0x34d8 0x3523 0x25d0 0x2ac6 0x31fe 0x347c 0x3522 0x35c2 0x25ce 0x2b56 0x31f8 0x34af 0x354f 0x3641 0x25cb 0x2a3a 0x31fd 0x34ab 0x358c 0x3650 0x25ca 0x2853 0x3202 0x34a2 0x35e1 0x3641 0x25c8 0x27f0 0x31f9 0x3495 0x3619 0x3642 0x25c7 0x28b1 0x31e1 0x347c 0x36d8 0x3664 0x25c6 0x2930 0x31be 0x3464 0x3754 0x368b 0x25c5 0x28c6 0x3188 0x3455 0x36ec 0x36af 0x25c5 0x2804 0x3134 0x344d 0x3640 0x36cd 0x25c4 0x2758 0x30af 0x3441 0x360a 0x36c2 0x25c4 0x26a6 0x2fbb 0x3409 0x35ce 0x365b 0x25c3 0x2630 0x2f20 0x33e4 0x357f 0x35dc 0x25c3 0x2605 0x2f0c 0x33e7 0x34f1 0x353c 0x25c3 0x25ee 0x2ef8 0x33d8 0x348c 0x34d5 0x25c3 0x25e2 0x2d76 0x3355 0x34df 0x356e 0x25c3 0x25d9 0x2c66 0x32d2 0x34c7 0x34c5 0x25c3 0x25d9 0x2d40 0x322f 0x3381 0x3374 0x25c2 0x25d8 0x2cd6 0x3289 0x33c7 0x333f 0x25c2 0x25d8 0x2cd1 0x3203 0x336c 0x32c8 0x25c2 0x25d8 0x2d07 0x326f 0x329a 0x32b2 0x25c2 0x25d9 0x2d15 0x324f 0x32f3 0x32b6 0x25c2 0x25d6 0x2ce8 0x31cb 0x3287 0x3286 0x25c2 0x25d2 0x2ca9 0x3129 0x31f6 0x313b 0x25c1 0x25cd 0x2bc3 0x308b 0x3204 0x3089 0x25c1 0x25ca 0x2af9 0x2f6a 0x30bf 0x2f9c 0x25c1 0x25ca 0x2af9 0x2f6a 0x30bf 0x2f9c 0x25c1 0x25ca 0x2af9 0x2f6a 0x30bf 0x2f9c>;
				};

				qcom,pc-temp-y3-lut {
					qcom,lut-col-legend = <0xfffffff6 0x00 0x0a 0x19 0x28 0x32>;
					qcom,lut-row-legend = <0x2710 0x2648 0x2580 0x24b8 0x23f0 0x2328 0x2260 0x2198 0x20d0 0x2008 0x1f40 0x1e78 0x1db0 0x1ce8 0x1c20 0x1b58 0x1a90 0x19c8 0x1900 0x1838 0x1770 0x16a8 0x15e0 0x1518 0x1450 0x1388 0x12c0 0x11f8 0x1130 0x1068 0xfa0 0xed8 0xe10 0xd48 0xc80 0xbb8 0xaf0 0xa28 0x960 0x898 0x7d0 0x708 0x640 0x578 0x4b0 0x3e8 0x384 0x320 0x2bc 0x258 0x1f4 0x190 0x12c 0xc8 0x64 0x00>;
					qcom,lut-data = <0x34b1 0x33fe 0x33e4 0x33d4 0x33d0 0x33cf 0x34a3 0x33fd 0x33e3 0x33d4 0x33d0 0x33cf 0x3496 0x33fc 0x33e3 0x33d4 0x33d1 0x33d0 0x348c 0x33fd 0x33e3 0x33d4 0x33d1 0x33d0 0x3485 0x33fe 0x33e4 0x33d5 0x33d2 0x33d0 0x3482 0x33ff 0x33e4 0x33d5 0x33d2 0x33d1 0x3485 0x3401 0x33e5 0x33d5 0x33d2 0x33d1 0x348a 0x3403 0x33e6 0x33d5 0x33d2 0x33d1 0x3482 0x3405 0x33e7 0x33d5 0x33d2 0x33d1 0x3450 0x3406 0x33e8 0x33d5 0x33d2 0x33d1 0x342d 0x3407 0x33e9 0x33d6 0x33d2 0x33d1 0x3434 0x340b 0x33e9 0x33d7 0x33d2 0x33d2 0x3440 0x340f 0x33e9 0x33d8 0x33d3 0x33d2 0x3442 0x340f 0x33e9 0x33d9 0x33d3 0x33d2 0x343d 0x3407 0x33ed 0x33da 0x33d3 0x33d2 0x343a 0x33ff 0x33ef 0x33da 0x33d4 0x33d2 0x343e 0x33fb 0x33ec 0x33da 0x33d3 0x33d2 0x3443 0x33f8 0x33e6 0x33da 0x33d3 0x33d2 0x3444 0x33f6 0x33e4 0x33da 0x33d3 0x33d2 0x3440 0x33f3 0x33e3 0x33db 0x33d5 0x33d3 0x343b 0x33f1 0x33e2 0x33db 0x33d6 0x33d4 0x3430 0x33ef 0x33e1 0x33da 0x33d4 0x33d3 0x3424 0x33ed 0x33df 0x33d7 0x33d2 0x33d1 0x3422 0x33ec 0x33de 0x33d5 0x33d1 0x33d0 0x3428 0x33eb 0x33dd 0x33d4 0x33d1 0x33d0 0x3432 0x33ea 0x33dd 0x33d4 0x33d1 0x33d0 0x343e 0x33e0 0x33dc 0x33d4 0x33d1 0x33d0 0x344e 0x33cf 0x33dc 0x33d3 0x33d1 0x33d0 0x3461 0x33cc 0x33dc 0x33d3 0x33d1 0x33d0 0x3479 0x33cb 0x33dc 0x33d3 0x33d1 0x33d0 0x3494 0x33cb 0x33dc 0x33d3 0x33d0 0x33d0 0x34b6 0x33cc 0x33db 0x33d4 0x33d0 0x33d0 0x34dd 0x33cd 0x33db 0x33d4 0x33d0 0x33d0 0x3508 0x33d0 0x33db 0x33d4 0x33d0 0x33d0 0x3538 0x33dc 0x33db 0x33d4 0x33d0 0x33cf 0x356c 0x33e8 0x33dc 0x33d3 0x33d0 0x33cf 0x35a6 0x33ee 0x33dc 0x33d3 0x33d0 0x33cf 0x35e5 0x33f4 0x33dc 0x33d3 0x33d0 0x33cf 0x3624 0x33f9 0x33dc 0x33d3 0x33d0 0x33cf 0x3662 0x33ff 0x33dc 0x33d3 0x33d1 0x33d0 0x36a1 0x3405 0x33dc 0x33d3 0x33d1 0x33d0 0x36e6 0x340e 0x33de 0x33d3 0x33d1 0x33d0 0x3729 0x341e 0x33e1 0x33d3 0x33d1 0x33d0 0x3762 0x3438 0x33e2 0x33d3 0x33d1 0x33cf 0x3791 0x3461 0x33e5 0x33d4 0x33d1 0x33cf 0x3764 0x346c 0x33e8 0x33d4 0x33d1 0x33d0 0x3761 0x347f 0x33ea 0x33d4 0x33d2 0x33d1 0x3779 0x348d 0x33ee 0x33d7 0x33d2 0x33d2 0x3795 0x3499 0x33f4 0x33d9 0x33d4 0x33d3 0x379f 0x349b 0x33f7 0x33d9 0x33d3 0x33d2 0x37a3 0x34a9 0x33f7 0x33d8 0x33d3 0x33d2 0x37c4 0x34c7 0x33f9 0x33d9 0x33d3 0x33d2 0x381d 0x34f5 0x33fd 0x33da 0x33d3 0x33d3 0x38a1 0x3533 0x340b 0x33dc 0x33d4 0x33d3 0x38a1 0x3533 0x340b 0x33dc 0x33d4 0x33d3 0x38a1 0x3533 0x340b 0x33dc 0x33d4 0x33d3>;
				};

				qcom,pc-temp-y4-lut {
					qcom,lut-col-legend = <0xfffffff6 0x00 0x0a 0x19 0x28 0x32>;
					qcom,lut-row-legend = <0x2710 0x2648 0x2580 0x24b8 0x23f0 0x2328 0x2260 0x2198 0x20d0 0x2008 0x1f40 0x1e78 0x1db0 0x1ce8 0x1c20 0x1b58 0x1a90 0x19c8 0x1900 0x1838 0x1770 0x16a8 0x15e0 0x1518 0x1450 0x1388 0x12c0 0x11f8 0x1130 0x1068 0xfa0 0xed8 0xe10 0xd48 0xc80 0xbb8 0xaf0 0xa28 0x960 0x898 0x7d0 0x708 0x640 0x578 0x4b0 0x3e8 0x384 0x320 0x2bc 0x258 0x1f4 0x190 0x12c 0xc8 0x64 0x00>;
					qcom,lut-data = <0x416d 0x40c6 0x4078 0x4038 0x4027 0x4022 0x41ac 0x40d0 0x4078 0x4035 0x4026 0x4022 0x41e6 0x40e2 0x4078 0x4033 0x4025 0x4021 0x4216 0x40f5 0x4077 0x4033 0x4024 0x4021 0x4237 0x4105 0x4076 0x4032 0x4023 0x4020 0x4245 0x410b 0x4076 0x4033 0x4023 0x4020 0x423a 0x410a 0x4074 0x4033 0x4023 0x4020 0x4227 0x4109 0x4073 0x4035 0x4023 0x4020 0x423e 0x410a 0x4073 0x4036 0x4023 0x4020 0x42df 0x4111 0x4078 0x4037 0x4024 0x4020 0x4388 0x411c 0x407e 0x4039 0x4025 0x4021 0x4409 0x4135 0x4083 0x403a 0x4027 0x4022 0x4475 0x415a 0x4088 0x403c 0x4029 0x4022 0x4443 0x4180 0x4096 0x4040 0x402b 0x4024 0x42a4 0x41af 0x40c1 0x4047 0x402e 0x4026 0x4182 0x41c9 0x40df 0x404f 0x4032 0x4028 0x418f 0x418c 0x40e4 0x4056 0x4036 0x402b 0x41a7 0x4124 0x40e8 0x405e 0x403a 0x402f 0x41a5 0x4104 0x40e7 0x406e 0x4044 0x4036 0x4172 0x40fd 0x40da 0x4090 0x4058 0x4045 0x4136 0x40f4 0x40c8 0x40a4 0x4063 0x404d 0x4100 0x40d5 0x409f 0x4082 0x4051 0x4041 0x40cf 0x40a9 0x406d 0x404b 0x4035 0x402c 0x40c0 0x4091 0x405a 0x4039 0x402b 0x4025 0x40bc 0x4082 0x4052 0x4032 0x4027 0x4023 0x40bb 0x407b 0x404e 0x4030 0x4026 0x4022 0x40bd 0x4083 0x404d 0x4030 0x4026 0x4022 0x40c2 0x4090 0x404c 0x4031 0x4027 0x4023 0x40c7 0x4092 0x404c 0x4033 0x4027 0x4024 0x40cd 0x408b 0x404c 0x4034 0x4029 0x4026 0x40d4 0x4086 0x404c 0x4037 0x402c 0x4028 0x40db 0x408a 0x404b 0x403b 0x402f 0x402b 0x40e3 0x408f 0x4049 0x4040 0x4033 0x402e 0x40ed 0x408f 0x4047 0x4041 0x4034 0x402f 0x40fb 0x408a 0x4047 0x403f 0x4035 0x402e 0x4105 0x4087 0x4046 0x403c 0x4035 0x402e 0x410a 0x408f 0x4047 0x4034 0x402f 0x402a 0x410e 0x40a0 0x4048 0x402c 0x4026 0x4025 0x4111 0x40ae 0x404a 0x402a 0x4023 0x4023 0x4116 0x40bb 0x404d 0x402a 0x4022 0x4023 0x411a 0x40c4 0x4050 0x402a 0x4022 0x4023 0x411e 0x40c6 0x4057 0x402b 0x4022 0x4022 0x4126 0x40c9 0x405e 0x402d 0x4022 0x4021 0x413f 0x40d6 0x4063 0x402b 0x401e 0x401d 0x416c 0x40f8 0x406f 0x402e 0x401f 0x401d 0x4173 0x411e 0x4074 0x4034 0x4025 0x4025 0x4180 0x4148 0x4085 0x403b 0x4029 0x402c 0x41aa 0x417f 0x40a3 0x4043 0x4033 0x4037 0x41dd 0x41c6 0x40d6 0x4057 0x4047 0x4057 0x421a 0x41eb 0x4106 0x4069 0x403e 0x4028 0x4235 0x4206 0x4106 0x4046 0x4025 0x4022 0x4236 0x4234 0x40f1 0x4044 0x4026 0x4024 0x4218 0x4266 0x40f9 0x404c 0x402b 0x402b 0x4214 0x42bb 0x4122 0x4064 0x4036 0x4037 0x4214 0x42bb 0x4122 0x4064 0x4036 0x4037 0x4214 0x42bb 0x4122 0x4064 0x4036 0x4037>;
				};

				qcom,pc-temp-y5-lut {
					qcom,lut-col-legend = <0xfffffff6 0x00 0x0a 0x19 0x28 0x32>;
					qcom,lut-row-legend = <0x2710 0x2648 0x2580 0x24b8 0x23f0 0x2328 0x2260 0x2198 0x20d0 0x2008 0x1f40 0x1e78 0x1db0 0x1ce8 0x1c20 0x1b58 0x1a90 0x19c8 0x1900 0x1838 0x1770 0x16a8 0x15e0 0x1518 0x1450 0x1388 0x12c0 0x11f8 0x1130 0x1068 0xfa0 0xed8 0xe10 0xd48 0xc80 0xbb8 0xaf0 0xa28 0x960 0x898 0x7d0 0x708 0x640 0x578 0x4b0 0x3e8 0x384 0x320 0x2bc 0x258 0x1f4 0x190 0x12c 0xc8 0x64 0x00>;
					qcom,lut-data = <0x40d5 0x5c92 0x603d 0x5766 0x670f 0x5723 0x3b07 0x5bd6 0x607e 0x5b06 0x6ae5 0x6356 0x386c 0x5b1d 0x6066 0x5c35 0x6f72 0x6f74 0x3860 0x5a67 0x601f 0x5bc8 0x73af 0x79fc 0x3a41 0x59b5 0x5fd5 0x5a97 0x7695 0x816a 0x3d6f 0x5908 0x5fb3 0x597b 0x771c 0x843a 0x48c5 0x585c 0x5fb2 0x56bd 0x75ad 0x8232 0x57b7 0x57b4 0x5f90 0x52d7 0x736d 0x7e63 0x56dd 0x5714 0x5ece 0x5103 0x6fe3 0x7bda 0x4132 0x561e 0x5bfc 0x4f17 0x6972 0x79ed 0x3269 0x5484 0x586c 0x4e0f 0x635a 0x7766 0x3dbb 0x4ce5 0x53fd 0x5152 0x5f15 0x7296 0x5075 0x4271 0x4f0b 0x5660 0x5b76 0x6c43 0x52bf 0x419b 0x4b94 0x562d 0x5871 0x66c5 0x4831 0x4955 0x48a7 0x5004 0x55dd 0x61a1 0x40c0 0x5129 0x4755 0x4c05 0x5340 0x5d2d 0x45b2 0x55f6 0x497b 0x4c53 0x4fa6 0x58cd 0x4eb9 0x5a0e 0x4e31 0x4d20 0x4c68 0x554c 0x5264 0x5d12 0x53b1 0x4ecc 0x4c83 0x54f1 0x5416 0x5fad 0x5b6b 0x53c2 0x50aa 0x5677 0x54d8 0x6119 0x60e8 0x5a38 0x563d 0x58f7 0x4ca7 0x615e 0x6351 0x6408 0x5d86 0x5f5d 0x3da3 0x6171 0x64ec 0x6e20 0x65c4 0x68ea 0x3818 0x61a7 0x650a 0x6fef 0x6b56 0x70c0 0x3659 0x62e9 0x6461 0x6cf1 0x6fbf 0x789c 0x3571 0x638b 0x63f3 0x6ad3 0x721e 0x7c6f 0x354c 0x5508 0x64f2 0x68a4 0x7105 0x78b5 0x359a 0x3ccf 0x6699 0x6543 0x6ea2 0x7202 0x35f5 0x3619 0x66fb 0x64a4 0x6d89 0x6dec 0x366a 0x34ee 0x6610 0x64e9 0x6a2d 0x6a45 0x3708 0x347e 0x65b3 0x656a 0x6764 0x676e 0x3836 0x3501 0x681e 0x6a55 0x64fb 0x6530 0x39b7 0x3660 0x6bb7 0x7218 0x622d 0x6362 0x3a69 0x38d0 0x6d58 0x74f5 0x62a6 0x63e9 0x3a8d 0x3e9e 0x6e59 0x7470 0x68b8 0x68e8 0x3ac0 0x4404 0x6ea8 0x73ae 0x7010 0x6ec8 0x3bb6 0x47b5 0x6cf0 0x729b 0x77d5 0x73c1 0x3d08 0x4ab6 0x6958 0x709d 0x7f81 0x78f3 0x3d13 0x4aa3 0x6402 0x6f49 0x834f 0x7eee 0x3ad2 0x45f6 0x5968 0x6dd0 0x8575 0x86bf 0x38fc 0x4173 0x5342 0x6b8f 0x86f1 0x8ace 0x38e2 0x3ded 0x5519 0x6467 0x8756 0x8807 0x38e1 0x3b41 0x56f6 0x5e99 0x8831 0x8217 0x3900 0x3af0 0x51e2 0x6822 0x8f90 0x720c 0x3a00 0x3be0 0x4ff2 0x6595 0x8666 0x73e1 0x4053 0x3eff 0x5378 0x5ae3 0x6b79 0x7170 0x42db 0x44cf 0x5025 0x53a2 0x713d 0x6a1c 0x4697 0x4984 0x4f5a 0x5c10 0x6624 0x6478 0x49ef 0x502b 0x5496 0x6409 0x6be3 0x6c1b 0x500a 0x539c 0x585b 0x63f3 0x67f0 0x81b7 0x50b0 0x5280 0x5a5f 0x6ad0 0x8770 0x8f52 0x4e3c 0x518c 0x5830 0x6c06 0x8277 0x8c77 0x4806 0x4cb5 0x5096 0x6260 0x7f12 0x8d14 0x3df0 0x43dd 0x49ef 0x61f6 0x6fd2 0x7181 0x3df0 0x43dd 0x49ef 0x61f6 0x6fd2 0x7181 0x3df0 0x43dd 0x49ef 0x61f6 0x6fd2 0x7181>;
				};

				qcom,pc-temp-y6-lut {
					qcom,lut-col-legend = <0xfffffff6 0x00 0x0a 0x19 0x28 0x32>;
					qcom,lut-row-legend = <0x2710 0x2648 0x2580 0x24b8 0x23f0 0x2328 0x2260 0x2198 0x20d0 0x2008 0x1f40 0x1e78 0x1db0 0x1ce8 0x1c20 0x1b58 0x1a90 0x19c8 0x1900 0x1838 0x1770 0x16a8 0x15e0 0x1518 0x1450 0x1388 0x12c0 0x11f8 0x1130 0x1068 0xfa0 0xed8 0xe10 0xd48 0xc80 0xbb8 0xaf0 0xa28 0x960 0x898 0x7d0 0x708 0x640 0x578 0x4b0 0x3e8 0x384 0x320 0x2bc 0x258 0x1f4 0x190 0x12c 0xc8 0x64 0x00>;
					qcom,lut-data = <0x15a0 0x1418 0x139e 0x1356 0x1349 0x1346 0x1591 0x141c 0x139c 0x1356 0x1349 0x1346 0x1587 0x141e 0x139a 0x1355 0x1349 0x1347 0x1581 0x141f 0x1399 0x1355 0x1349 0x1347 0x157d 0x141f 0x1397 0x1355 0x1349 0x1347 0x157d 0x141f 0x1395 0x1355 0x1349 0x1347 0x1580 0x141d 0x1394 0x1355 0x1349 0x1347 0x1586 0x141a 0x1393 0x1355 0x1349 0x1347 0x1588 0x1419 0x1393 0x1355 0x134a 0x1347 0x1587 0x141a 0x1394 0x1356 0x134a 0x1348 0x1587 0x141a 0x1395 0x1357 0x134a 0x1348 0x15a4 0x1421 0x1395 0x1358 0x134b 0x1348 0x15d1 0x142c 0x1396 0x1359 0x134b 0x1349 0x15c7 0x1433 0x1399 0x135b 0x134c 0x1349 0x1553 0x1438 0x13a7 0x135d 0x134d 0x134a 0x1501 0x143a 0x13b0 0x1360 0x134e 0x134a 0x1507 0x1428 0x13af 0x1362 0x134f 0x134b 0x1512 0x1408 0x13ac 0x1364 0x1351 0x134d 0x1512 0x13fc 0x13a9 0x1369 0x1353 0x134f 0x1505 0x13f9 0x13a5 0x1373 0x135a 0x1354 0x14f5 0x13f5 0x139f 0x1379 0x135e 0x1356 0x14e5 0x13ea 0x1392 0x136e 0x1358 0x1352 0x14d7 0x13de 0x1383 0x135c 0x134e 0x134b 0x14d5 0x13d7 0x137d 0x1356 0x134a 0x1348 0x14de 0x13d5 0x137a 0x1353 0x1349 0x1347 0x14ec 0x13d2 0x1379 0x1352 0x1348 0x1347 0x14fb 0x13ce 0x1379 0x1352 0x1349 0x1347 0x150d 0x13cb 0x1379 0x1353 0x1349 0x1347 0x1522 0x13cb 0x1379 0x1353 0x1349 0x1347 0x1539 0x13cb 0x137a 0x1354 0x1349 0x1348 0x1554 0x13cd 0x137a 0x1355 0x134a 0x1348 0x1572 0x13d1 0x137a 0x1356 0x134b 0x1349 0x1594 0x13d8 0x137b 0x1358 0x134c 0x134a 0x15b9 0x13df 0x137b 0x1359 0x134d 0x134b 0x15e1 0x13e9 0x137b 0x1358 0x134d 0x134a 0x160b 0x13f5 0x137c 0x1357 0x134d 0x134a 0x1638 0x1404 0x137e 0x1355 0x134b 0x1349 0x1667 0x1415 0x1380 0x1353 0x1349 0x1348 0x1695 0x1428 0x1382 0x1352 0x1348 0x1347 0x16c3 0x143c 0x1384 0x1352 0x1348 0x1348 0x16f3 0x1453 0x1388 0x1353 0x1348 0x1348 0x1726 0x146b 0x138e 0x1354 0x1349 0x1348 0x175b 0x1488 0x1395 0x1354 0x1349 0x1347 0x178c 0x14b0 0x139b 0x1355 0x1348 0x1345 0x17ba 0x14e6 0x13a7 0x1356 0x1348 0x1346 0x179c 0x14f5 0x13ac 0x1359 0x134a 0x1349 0x179e 0x150f 0x13b5 0x135b 0x134c 0x134c 0x17bc 0x152a 0x13c4 0x135f 0x134f 0x134f 0x17e2 0x1546 0x13da 0x1367 0x1356 0x1359 0x17fb 0x1553 0x13eb 0x136c 0x1353 0x134b 0x1806 0x156b 0x13ec 0x1362 0x134b 0x134a 0x1823 0x1597 0x13eb 0x1363 0x134c 0x134b 0x185f 0x15cf 0x13fa 0x1367 0x134f 0x134d 0x18c0 0x1620 0x1420 0x1371 0x1352 0x1351 0x18c0 0x1620 0x1420 0x1371 0x1352 0x1351 0x18c0 0x1620 0x1420 0x1371 0x1352 0x1351>;
				};
			};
